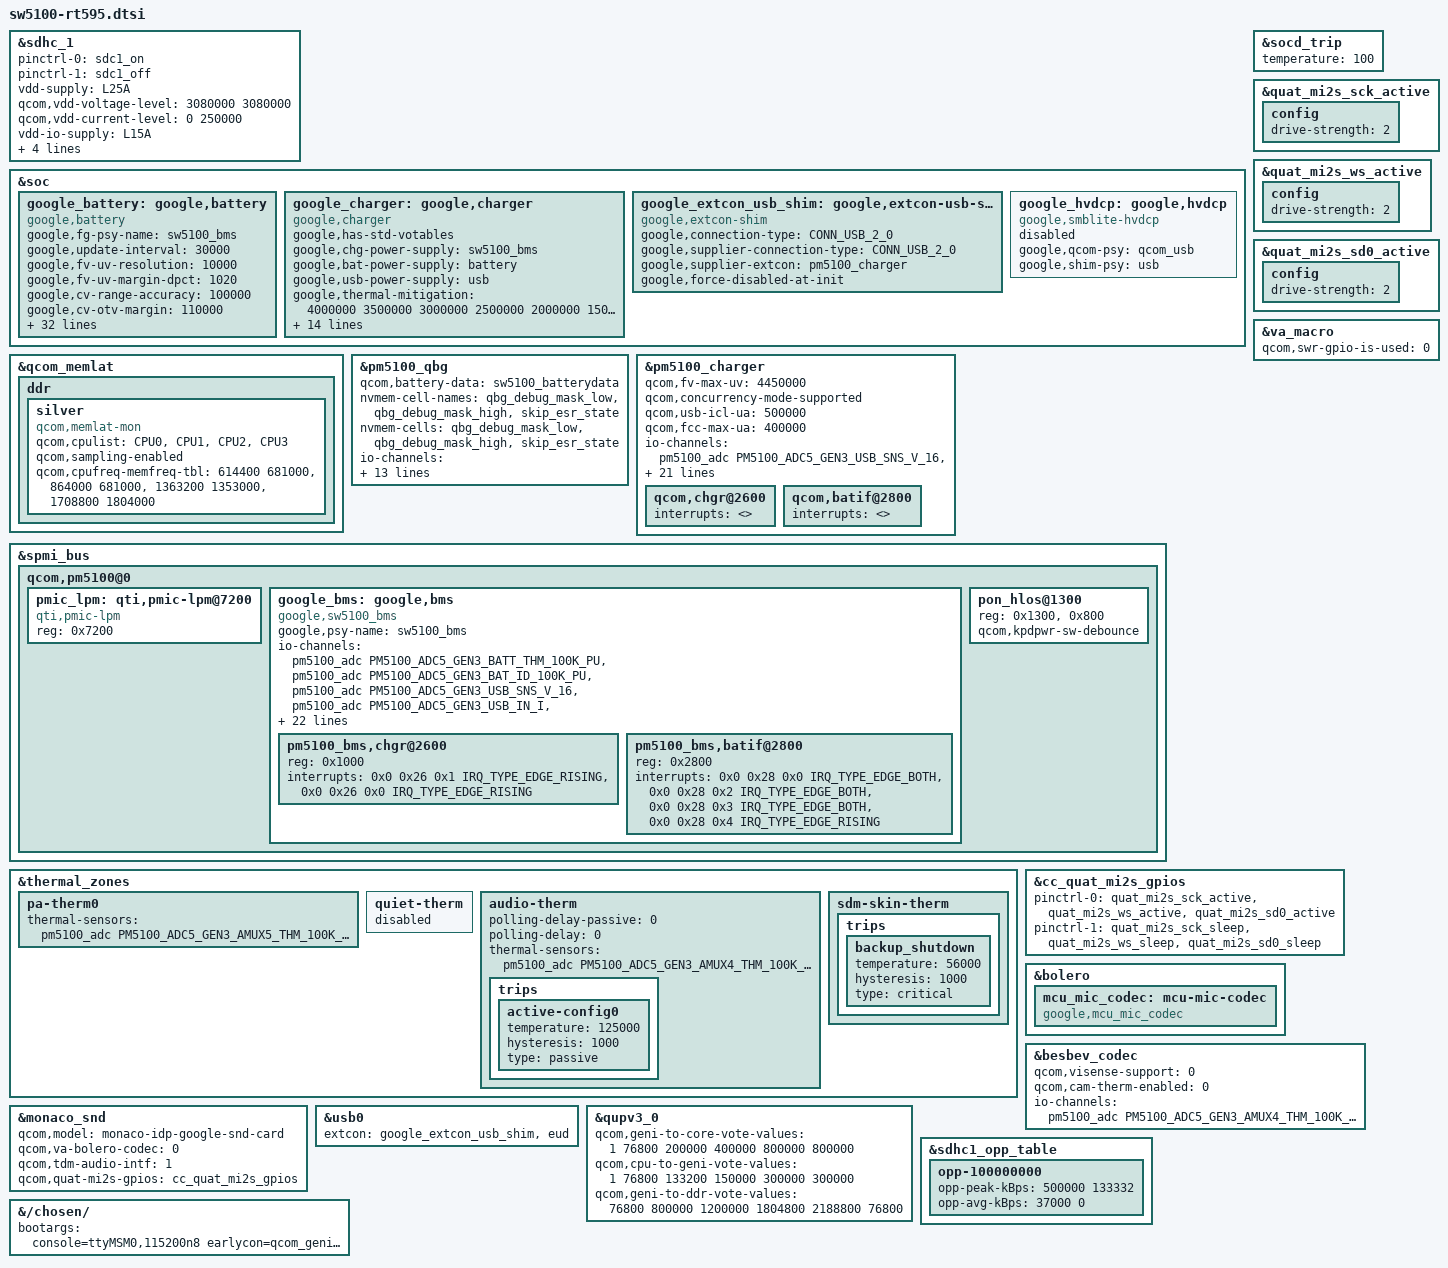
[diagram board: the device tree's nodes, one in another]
// SPDX-License-Identifier: GPL-2.0
// base on: monaco-standalone-idp-v1.dtsi

#include "../vendor/qcom/monaco-thermal-overlay.dtsi"
#include <dt-bindings/iio/qcom,spmi-adc5-gen3-pm5100.h>
#include <dt-bindings/iio/qti_power_supply_iio.h>
#include <dt-bindings/clock/qcom,rpmcc.h>
#include <dt-bindings/interrupt-controller/irq.h>
#include <dt-bindings/extcon/google,extcon-shim.h>

&sdhc_1 {
	status = "ok";

	pinctrl-names = "default", "sleep";
	pinctrl-0 = <&sdc1_on>;
	pinctrl-1 = <&sdc1_off>;

	vdd-supply = <&L25A>;
	qcom,vdd-voltage-level = <3080000 3080000>;
	qcom,vdd-current-level = <0 250000>;

	vdd-io-supply = <&L15A>;
	qcom,vdd-io-always-on;
	qcom,vdd-io-lpm-sup;
	qcom,vdd-io-voltage-level = <1800000 1800000>;
	qcom,vdd-io-current-level = <0 250000>;
};

&soc {
	google_battery: google,battery {
		compatible = "google,battery";
		google,fg-psy-name = "sw5100_bms";

		/* battery poll rate */
		google,update-interval = <30000>;
		/* IRDrop Compensation */
		google,fv-uv-resolution = <10000>;
		google,fv-uv-margin-dpct = <1020>;
		/* tier switch */
		google,cv-range-accuracy = <100000>;
		google,cv-otv-margin = <110000>;
		google,cv-debounce-cnt = <3>;
		google,cv-tier-ov-cnt = <1>;
		google,cv-tier-switch-cnt = <3>;
		/* resistance estimation */
		google,res-temp-hi = <390>;
		google,res-temp-lo = <350>;
		google,res-soc-thresh = <75>;
		google,res-filt-length = <10>;
		/* enable cycle counts */
		google,cycle-counts;
		google,zero-ibat-offset = <(-30500)>;

		#thermal-sensor-cells = <0>;
		/* soc smoothing */
		google,rl_delta-max-soc = <2>;
		google,rl_delta-max-time = <15>;
		google,rl_ft-low-limit = <7>;
		google,rl_ft-delta-limit = <15>;
		google,rl_st-delta-limit = <7>;
		google,rl_st-max-count = <3>;
		google,rl_no-zero;
		google,rl_soc-limits = <20 30 40 50 60 70 90 100>;
		google,rl_soc-rates =  <25 26 27 28 29 28 27 22>;
		/* rest charging */
		google,chg-rest-rate = <15>;
		google,chg-rest-soc = <80>;

		/* battery history */

		google,recharge-soc-threshold = <95>;
		google,ssoc-delta = <2>;
		/* TRICKLE-DEFEND threshold */
		google,bd-trickle-recharge-soc = <80>;

		/* decide boot to OS or off-mode charging, needs HW support */
		google,shutdown-flag-disable;

		/* Delay 3000 ms between retries until sw5100_bms is ready */
		google,batt-init-delay = <3000>;

		/* Ignore the initial soc(power-on soc) since it is not accurate */
		/* restart the calculation after receiving the update from hvdcp_opti */
		google,batt-ignore-pon-soc;

		google,chg-battery-capacity = <306>;

		google,chg-cc-ua-resolution = <25000>;

		/* charge table */
		google,chg-temp-limits = <0 100 415 450>;
		google,chg-cv-limits = <4450000>;
		/* units are C rate in percent */
		google,chg-cc-limits = <
			41
			131
			41
		>;

		/*
		 * Delay shutdown due to discharging battery at 0% SOC by
		 * 110 seconds.
		 */
		google,vbatt-crit-deadline-sec = <110>;
	};

	google_charger: google,charger {
		compatible = "google,charger";
		#cooling-cells = <2>;
		google,has-std-votables;
		google,chg-power-supply = "sw5100_bms";
		google,bat-power-supply = "battery";
		google,usb-power-supply = "usb";
		google,thermal-mitigation = <4000000 3500000 3000000
						2500000 2000000 1500000
						1000000 500000>;
		//google,thermal-pd-wa;
		google,fv-max-uv = <4450000>;
		google,chg-termination-5v;

		/* b/170700459 thresholds */
		google,bd-resume-abs-temp = <280>;
		google,bd-resume-time = <14400>;  /* 4 hours */
		google,bd-resume-temp = <290>;
		google,bd-resume-soc = <50>;
		google,bd-trigger-time = <21600>; /* 6 hours */
		google,bd-trigger-temp = <350>;
		google,bd-trigger-voltage = <4320000>;
		google,bd-recharge-voltage = <4300000>;
		google,bd-drainto-soc = <80>;
		google,bd-recharge-soc = <79>;
		/* Enable TEMP-DEFEND */
		google,bd-temp-enable;
		google,bd-temp-dry-run;
	};

	google_extcon_usb_shim: google,extcon-usb-shim {
		compatible = "google,extcon-shim";
		google,connection-type = <CONN_USB_2_0>;
		google,supplier-connection-type = <CONN_USB_2_0>;
		google,supplier-extcon = <&pm5100_charger>;
		google,force-disabled-at-init;
	};

	google_hvdcp: google,hvdcp {
		compatible = "google,smblite-hvdcp";
		google,qcom-psy = "qcom_usb";
		google,shim-psy = "usb";
		status = "disabled";
	};
};

&qcom_memlat {
	ddr {
		silver {
			compatible = "qcom,memlat-mon";
			qcom,cpulist = <&CPU0 &CPU1 &CPU2 &CPU3>;
			qcom,sampling-enabled;
			qcom,cpufreq-memfreq-tbl =
				< 614400 681000 >,
				< 864000 681000 >,
				< 1363200 1353000 >,
				< 1708800 1804000 >;
		};
	};
};

&pm5100_qbg {
	status = "ok";
	qcom,battery-data = <&sw5100_batterydata>;
	nvmem-cell-names = "qbg_debug_mask_low", "qbg_debug_mask_high", "skip_esr_state";
	nvmem-cells = <&qbg_debug_mask_low>, <&qbg_debug_mask_high>, <&skip_esr_state>;
	#io-channel-cells = <1>;
	io-channels = <&pm5100_adc PM5100_ADC5_GEN3_BATT_THM_100K_PU>,
		      <&pm5100_adc PM5100_ADC5_GEN3_BAT_ID_100K_PU>,
		      <&pm5100_charger PSY_IIO_CHARGE_DONE>,
		      <&pm5100_charger PSY_IIO_RECHARGE_SOC>,
		      <&pm5100_charger PSY_IIO_FORCE_RECHARGE>,
		      <&pm5100_charger PSY_IIO_SYS_SOC>;
	io-channel-names = "batt-temp",
			   "batt-id",
			   "charge_done",
			   "recharge_soc",
			   "force_recharge",
			   "sys_soc";
	qcom,vbat-cutoff-mv = <3100>;
	qcom,ibat-cutoff-ma = <10>;
	qcom,vph-min-mv = <2500>;
	qcom,iterm-ma = <30>;
	/*SOC delta (in percent) dropped from EOC SOC to enable recharge*/
	qcom,recharge-soc-delta =<5>;
	/*vfloat delta (in mV) dropped from regular vfloat in recharge*/
	qcom,recharge-vflt-delta =<0>;
	/*termination current (in mA) in recharge*/
	qcom,recharge-iterm-ma = <30>;
};

&pm5100_charger {
	qcom,fv-max-uv = <4450000>;
	qcom,concurrency-mode-supported;
	qcom,usb-icl-ua = <500000>;
	qcom,fcc-max-ua = <400000>;
	#io-channel-cells = <1>;
	io-channels = <&pm5100_adc PM5100_ADC5_GEN3_USB_SNS_V_16>,
		      <&pm5100_adc PM5100_ADC5_GEN3_USB_IN_I>,
		      <&pm5100_adc PM5100_ADC5_GEN3_CHG_TEMP>,
		      <&pm5100_adc PM5100_ADC5_GEN3_DIE_TEMP>,
		      <&pm5100_adc PM5100_ADC5_GEN3_VPH_PWR>,
		      <&pm5100_qbg PSY_IIO_RESISTANCE_ID>,
		      <&pm5100_qbg PSY_IIO_VOLTAGE_NOW>,
		      <&pm5100_qbg PSY_IIO_TEMP>,
		      <&pm5100_qbg PSY_IIO_CAPACITY>,
		      <&pm5100_qbg PSY_IIO_VOLTAGE_OCV>,
		      <&pm5100_qbg PSY_IIO_VOLTAGE_AVG>,
		      <&pm5100_qbg PSY_IIO_DEBUG_BATTERY>,
		      <&pm5100_qbg PSY_IIO_CURRENT_NOW>,
		      <&pm5100_qbg PSY_IIO_VOLTAGE_MAX>,
		      <&pm5100_qbg PSY_IIO_CHARGE_FULL>,
		      <&pm5100_qbg PSY_IIO_CHARGE_COUNTER>,
		      <&pm5100_qbg PSY_IIO_CYCLE_COUNT>,
		      <&pm5100_qbg PSY_IIO_CHARGE_FULL_DESIGN>,
		      <&pm5100_qbg PSY_IIO_TIME_TO_FULL_NOW>;

	io-channel-names = "usb_in_voltage",
			   "usb_in_current",
			   "chg_temp",
			   "die_temp",
			   "vph_voltage",
			   "resistance_id",
			   "voltage_now",
			   "temp",
			   "capacity",
			   "voltage_ocv",
			   "voltage_avg",
			   "debug_battery",
			   "current_now",
			   "voltage_max",
			   "charge_full",
			   "charge_counter",
			   "cycle_count",
			   "charge_full_design",
			   "time_to_full_now";

	google,batt_psy_disable;
	qcom,auto-recharge-vbat-mv = <4100>;
	qcom,auto-recharge-soc = <>;
	qcom,chgr@2600 {
		interrupts = <>;
		interrupt-names = <>;
	};
	qcom,batif@2800 {
		interrupts = <>;
		interrupt-names = <>;
	};
};

&spmi_bus {
	qcom,pm5100@0 {
		#address-cells = <1>;
		#size-cells = <0>;

		pmic_lpm: qti,pmic-lpm@7200 {
			compatible = "qti,pmic-lpm";
			reg = <0x7200>;
		};
		google_bms: google,bms {
			compatible = "google,sw5100_bms";
			google,psy-name = "sw5100_bms";
			io-channels = <&pm5100_adc PM5100_ADC5_GEN3_BATT_THM_100K_PU>,
				      <&pm5100_adc PM5100_ADC5_GEN3_BAT_ID_100K_PU>,
				      <&pm5100_adc PM5100_ADC5_GEN3_USB_SNS_V_16>,
				      <&pm5100_adc PM5100_ADC5_GEN3_USB_IN_I>,
				      <&pm5100_adc PM5100_ADC5_GEN3_CHG_TEMP>,
				      <&pm5100_adc PM5100_ADC5_GEN3_DIE_TEMP>,
				      <&pm5100_adc PM5100_ADC5_GEN3_VPH_PWR>,
				      <&pm5100_qbg PSY_IIO_RESISTANCE_ID>,
				      <&pm5100_qbg PSY_IIO_VOLTAGE_NOW>,
				      <&pm5100_qbg PSY_IIO_TEMP>,
				      <&pm5100_qbg PSY_IIO_CAPACITY>,
				      <&pm5100_qbg PSY_IIO_REAL_CAPACITY>,
				      <&pm5100_qbg PSY_IIO_VOLTAGE_OCV>,
				      <&pm5100_qbg PSY_IIO_VOLTAGE_AVG>,
				      <&pm5100_qbg PSY_IIO_DEBUG_BATTERY>,
				      <&pm5100_qbg PSY_IIO_CURRENT_NOW>,
				      <&pm5100_qbg PSY_IIO_VOLTAGE_MAX>,
				      <&pm5100_qbg PSY_IIO_CHARGE_FULL>,
				      <&pm5100_qbg PSY_IIO_CHARGE_COUNTER>,
				      <&pm5100_qbg PSY_IIO_CYCLE_COUNT>,
				      <&pm5100_qbg PSY_IIO_CHARGE_FULL_DESIGN>,
				      <&pm5100_qbg PSY_IIO_TIME_TO_FULL_NOW>,
				      <&pm5100_qbg PSY_IIO_TIME_TO_EMPTY_AVG>;


			io-channel-names = "batt-therm",
					   "batt-id",
					   "usb_in_voltage",
					   "usb_in_current",
					   "chg_temp",
					   "die_temp",
					   "vph_voltage",
					   "resistance_id",
					   "voltage_now",
					   "temp",
					   "capacity",
					   "real_capacity",
					   "voltage_ocv",
					   "voltage_avg",
					   "debug_battery",
					   "current_now",
					   "voltage_max",
					   "charge_full",
					   "charge_counter",
					   "cycle_count",
					   "charge_full_design",
					   "time_to_full_now",
					   "time_to_empty_avg";


			google,chg-term-voltage = <4440>;
			google,chg-term-voltage-debounce = <5>;

			google,soc_shutdown_offset = <5>;

			pm5100_bms,chgr@2600 {
				reg = <0x1000>;
				interrupts =
					<0x0 0x26 0x1 IRQ_TYPE_EDGE_RISING>,
					<0x0 0x26 0x0 IRQ_TYPE_EDGE_RISING>;
				interrupt-names =
					"chgr-error",
					"chg-state-change";
			};

			pm5100_bms,batif@2800 {
				reg = <0x2800>;
				interrupts =
					<0x0 0x28 0x0 IRQ_TYPE_EDGE_BOTH>,
					<0x0 0x28 0x2 IRQ_TYPE_EDGE_BOTH>,
					<0x0 0x28 0x3 IRQ_TYPE_EDGE_BOTH>,
					<0x0 0x28 0x4 IRQ_TYPE_EDGE_RISING>;

				interrupt-names = "bat-temp",
						  "bat-low",
						  "bat-ov",
						  "bsm-active";
			};
		};

		pon_hlos@1300 {
			reg = <0x1300>, <0x800>;
			qcom,kpdpwr-sw-debounce;
		};
	};
};

&thermal_zones {
	pa-therm0 {
		thermal-sensors = <&pm5100_adc PM5100_ADC5_GEN3_AMUX5_THM_100K_PU>;
	};

	quiet-therm {
		status = "disable";
	};

	audio-therm {
		polling-delay-passive = <0>;
		polling-delay = <0>;
		thermal-sensors = <&pm5100_adc PM5100_ADC5_GEN3_AMUX4_THM_100K_PU>;
		trips {
			active-config0 {
				temperature = <125000>;
				hysteresis = <1000>;
				type = "passive";
			};
		};
	};

	sdm-skin-therm {
		trips {
			backup_shutdown {
				temperature = <56000>;
				hysteresis = <1000>;
				type = "critical";
			};
		};
	};
};

&socd_trip {
	temperature = <100>;
};

&quat_mi2s_sck_active {
	config {
		drive-strength = <2>;   /* 2 mA */
	};
};

&quat_mi2s_ws_active {
	config {
		drive-strength = <2>;   /* 2 mA */
	};
};

&quat_mi2s_sd0_active {
	config {
		drive-strength = <2>;   /* 2 mA */
	};
};

&va_macro {
	qcom,swr-gpio-is-used = <0>;
};

&cc_quat_mi2s_gpios {
		pinctrl-0 = <&quat_mi2s_sck_active &quat_mi2s_ws_active
				&quat_mi2s_sd0_active>;

		pinctrl-1 = < &quat_mi2s_sck_sleep &quat_mi2s_ws_sleep
				&quat_mi2s_sd0_sleep>;
};

&bolero {
	mcu_mic_codec: mcu-mic-codec {
		status = "ok";
		compatible = "google,mcu_mic_codec";
	};
};

&besbev_codec {
	qcom,visense-support = <0>;
	qcom,cam-therm-enabled = <0>;
	io-channels = <&pm5100_adc PM5100_ADC5_GEN3_AMUX4_THM_100K_PU>;
	io-channel-names = "cam_therm";
};

&monaco_snd {
	qcom,model = "monaco-idp-google-snd-card";
	qcom,va-bolero-codec = <0>;

	qcom,tdm-audio-intf = <1>;
	qcom,quat-mi2s-gpios = <&cc_quat_mi2s_gpios>;
};

&usb0 {
	extcon = <&google_extcon_usb_shim>, <&eud>;
};

&qupv3_0 {
	qcom,geni-to-core-vote-values = <1 76800 200000 400000 800000 800000>;
	qcom,cpu-to-geni-vote-values = <1 76800 133200 150000 300000 300000>;
	qcom,geni-to-ddr-vote-values = <76800 800000 1200000 1804800  2188800 76800>;
};

&sdhc1_opp_table {
	opp-100000000 {
		opp-peak-kBps = <500000 133332>;
		opp-avg-kBps = <37000 0>;
	};
};

/ {
	fragment@rt595 {
		target-path = "/chosen/";
		__overlay__ {
			bootargs = "console=ttyMSM0,115200n8 earlycon=qcom_geni,0x4a98000 qcom_geni_serial.con_enabled=1 loglevel=6 kpti=off log_buf_len=256K kernel.panic_on_rcu_stall=1 msm_rtb.filter=0x237 rcupdate.rcu_expedited=1 rcu_nocbs=0-3 ftrace_dump_on_oops firmware_class.path=/vendor/firmware fw_devlink.strict=1 irqaffinity=0-2 cpufreq.default_governor=performance";
		};
	};
};
